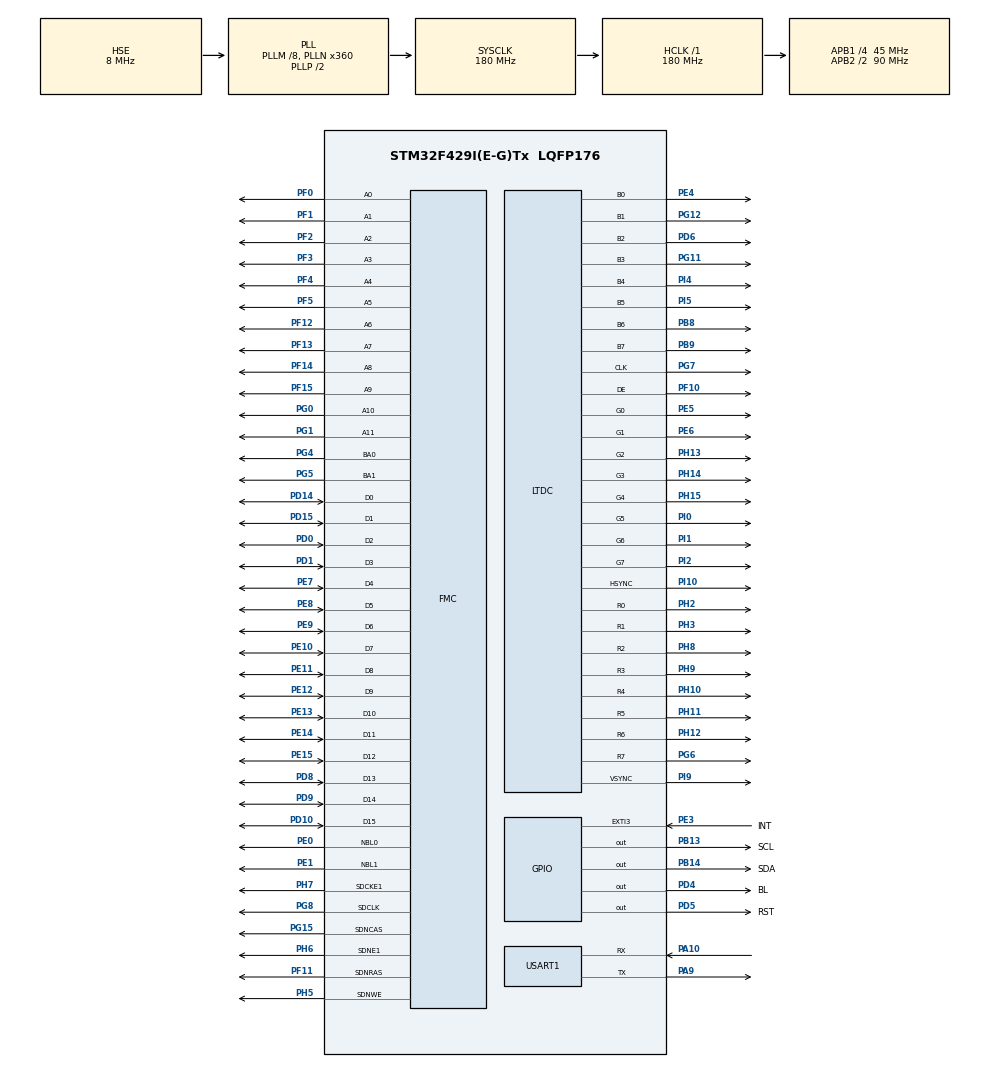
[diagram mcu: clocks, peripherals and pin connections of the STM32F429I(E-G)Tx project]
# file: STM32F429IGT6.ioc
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DMA2D.ColorMode=DMA2D_OUTPUT_RGB565
FMC.CASLatency1=FMC_SDRAM_CAS_LATENCY_3
FMC.ExitSelfRefreshDelay1=7
FMC.LoadToActiveDelay1=2
FMC.RCDDelay1=2
FMC.RPDelay1=2
FMC.ReadPipeDelay1=FMC_SDRAM_RPIPE_DELAY_1
FMC.RowCycleDelay1=6
FMC.SDClockPeriod1=FMC_SDRAM_CLOCK_PERIOD_2
FMC.SelfRefreshTime1=4
FMC.WriteRecoveryTime1=2
LTDC.ActiveW=800
LTDC.Alpha_L0=255
LTDC.FBStartAdress_L0=0xD0000000
LTDC.FBStartAdress_L1=0xD0200000
LTDC.HBP=30
LTDC.HFP=210
LTDC.HSync=30
LTDC.ImageHeight_L0=480
LTDC.ImageHeight_L1=480
LTDC.ImageWidth_L0=800
LTDC.ImageWidth_L1=800
LTDC.PixelFormat_L0=LTDC_PIXEL_FORMAT_RGB565
LTDC.PixelFormat_L1=LTDC_PIXEL_FORMAT_RGB565
LTDC.VBP=4
LTDC.VFP=4
LTDC.WindowX1_L0=800
LTDC.WindowX1_L1=800
LTDC.WindowY1_L0=480
LTDC.WindowY1_L1=480
Mcu.Family=STM32F4
Mcu.Name=STM32F429I(E-G)Tx
Mcu.Package=LQFP176
NVIC.EXTI3_IRQn=true\:3\:0\:true\:false\:true\:true
NVIC.PriorityGroup=NVIC_PRIORITYGROUP_4
PA10.Mode=Asynchronous
PA10.Signal=USART1_RX
PA9.Mode=Asynchronous
PA9.Signal=USART1_TX
PB13.GPIO_Label=SCL
PB13.GPIO_PuPd=GPIO_PULLUP
PB13.Signal=GPIO_Output
PB14.GPIO_Label=SDA
PB14.GPIO_PuPd=GPIO_PULLUP
PB14.Signal=GPIO_Output
PB8.GPIO_Speed=GPIO_SPEED_FREQ_VERY_HIGH
PB8.Mode=RGB888
PB8.Signal=LTDC_B6
PB9.GPIO_Speed=GPIO_SPEED_FREQ_VERY_HIGH
PB9.Mode=RGB888
PB9.Signal=LTDC_B7
PD0.Signal=FMC_D2_DA2
PD1.Signal=FMC_D3_DA3
PD10.Signal=FMC_D15_DA15
PD14.Signal=FMC_D0_DA0
PD15.Signal=FMC_D1_DA1
PD4.GPIO_Label=BL
PD4.GPIO_PuPd=GPIO_NOPULL
PD4.PinState=GPIO_PIN_RESET
PD4.Signal=GPIO_Output
PD5.GPIO_Label=RST
PD5.GPIO_PuPd=GPIO_PULLUP
PD5.Signal=GPIO_Output
PD6.GPIO_Speed=GPIO_SPEED_FREQ_VERY_HIGH
PD6.Mode=RGB888
PD6.Signal=LTDC_B2
PD8.Signal=FMC_D13_DA13
PD9.Signal=FMC_D14_DA14
PE0.Signal=FMC_NBL0
PE1.Signal=FMC_NBL1
PE10.Signal=FMC_D7_DA7
PE11.Signal=FMC_D8_DA8
PE12.Signal=FMC_D9_DA9
PE13.Signal=FMC_D10_DA10
PE14.Signal=FMC_D11_DA11
PE15.Signal=FMC_D12_DA12
PE3.GPIO_Label=INT
PE3.GPIO_ModeDefaultEXTI=GPIO_MODE_IT_FALLING
PE3.GPIO_PuPd=GPIO_PULLUP
PE3.Signal=GPXTI3
PE4.GPIO_Speed=GPIO_SPEED_FREQ_VERY_HIGH
PE4.Mode=RGB888
PE4.Signal=LTDC_B0
PE5.GPIO_Speed=GPIO_SPEED_FREQ_VERY_HIGH
PE5.Mode=RGB888
PE5.Signal=LTDC_G0
PE6.GPIO_Speed=GPIO_SPEED_FREQ_VERY_HIGH
PE6.Mode=RGB888
PE6.Signal=LTDC_G1
PE7.Signal=FMC_D4_DA4
PE8.Signal=FMC_D5_DA5
PE9.Signal=FMC_D6_DA6
PF0.Signal=FMC_A0
PF1.Signal=FMC_A1
PF10.GPIO_Speed=GPIO_SPEED_FREQ_VERY_HIGH
PF10.Mode=RGB888
PF10.Signal=LTDC_DE
PF11.Signal=FMC_SDNRAS
PF12.Signal=FMC_A6
PF13.Signal=FMC_A7
PF14.Signal=FMC_A8
PF15.Signal=FMC_A9
PF2.Signal=FMC_A2
PF3.Signal=FMC_A3
PF4.Signal=FMC_A4
PF5.Signal=FMC_A5
PG0.Signal=FMC_A10
PG1.Signal=FMC_A11
PG11.GPIO_Speed=GPIO_SPEED_FREQ_VERY_HIGH
PG11.Mode=RGB888
PG11.Signal=LTDC_B3
PG12.GPIO_Speed=GPIO_SPEED_FREQ_VERY_HIGH
PG12.Mode=RGB888
PG12.Signal=LTDC_B1
PG15.Signal=FMC_SDNCAS
PG4.Signal=FMC_A14_BA0
PG5.Signal=FMC_A15_BA1
PG6.GPIO_Speed=GPIO_SPEED_FREQ_VERY_HIGH
PG6.Mode=RGB888
PG6.Signal=LTDC_R7
PG7.GPIO_Speed=GPIO_SPEED_FREQ_VERY_HIGH
PG7.Mode=RGB888
PG7.Signal=LTDC_CLK
PG8.Signal=FMC_SDCLK
PH0/OSC_IN.Mode=HSE-External-Oscillator
PH0/OSC_IN.Signal=RCC_OSC_IN
PH1/OSC_OUT.Mode=HSE-External-Oscillator
PH1/OSC_OUT.Signal=RCC_OSC_OUT
PH10.GPIO_Speed=GPIO_SPEED_FREQ_VERY_HIGH
PH10.Mode=RGB888
PH10.Signal=LTDC_R4
PH11.GPIO_Speed=GPIO_SPEED_FREQ_VERY_HIGH
PH11.Mode=RGB888
PH11.Signal=LTDC_R5
PH12.GPIO_Speed=GPIO_SPEED_FREQ_VERY_HIGH
PH12.Mode=RGB888
PH12.Signal=LTDC_R6
PH13.GPIO_Speed=GPIO_SPEED_FREQ_VERY_HIGH
PH13.Mode=RGB888
PH13.Signal=LTDC_G2
PH14.GPIO_Speed=GPIO_SPEED_FREQ_VERY_HIGH
PH14.Mode=RGB888
PH14.Signal=LTDC_G3
PH15.GPIO_Speed=GPIO_SPEED_FREQ_VERY_HIGH
PH15.Mode=RGB888
PH15.Signal=LTDC_G4
PH2.GPIO_Speed=GPIO_SPEED_FREQ_VERY_HIGH
PH2.Mode=RGB888
PH2.Signal=LTDC_R0
PH3.GPIO_Speed=GPIO_SPEED_FREQ_VERY_HIGH
PH3.Mode=RGB888
PH3.Signal=LTDC_R1
PH5.Signal=FMC_SDNWE
PH6.Mode=SdramChipSelect2_1
PH6.Signal=FMC_SDNE1
PH7.Mode=SdramChipSelect2_1
PH7.Signal=FMC_SDCKE1
PH8.GPIO_Speed=GPIO_SPEED_FREQ_VERY_HIGH
PH8.Mode=RGB888
PH8.Signal=LTDC_R2
PH9.GPIO_Speed=GPIO_SPEED_FREQ_VERY_HIGH
PH9.Mode=RGB888
PH9.Signal=LTDC_R3
PI0.GPIO_Speed=GPIO_SPEED_FREQ_VERY_HIGH
PI0.Mode=RGB888
PI0.Signal=LTDC_G5
PI1.GPIO_Speed=GPIO_SPEED_FREQ_VERY_HIGH
PI1.Mode=RGB888
PI1.Signal=LTDC_G6
PI10.GPIO_Speed=GPIO_SPEED_FREQ_VERY_HIGH
PI10.Mode=RGB888
PI10.Signal=LTDC_HSYNC
PI2.GPIO_Speed=GPIO_SPEED_FREQ_VERY_HIGH
PI2.Mode=RGB888
PI2.Signal=LTDC_G7
PI4.GPIO_Speed=GPIO_SPEED_FREQ_VERY_HIGH
PI4.Mode=RGB888
PI4.Signal=LTDC_B4
PI5.GPIO_Speed=GPIO_SPEED_FREQ_VERY_HIGH
PI5.Mode=RGB888
PI5.Signal=LTDC_B5
PI9.GPIO_Speed=GPIO_SPEED_FREQ_VERY_HIGH
PI9.Mode=RGB888
PI9.Signal=LTDC_VSYNC
ProjectManager.HeapSize=0x200
ProjectManager.StackSize=0x400
ProjectManager.TargetToolchain=MDK-ARM V5
RCC.48MHZClocksFreq_Value=90000000
RCC.AHBFreq_Value=180000000
RCC.APB1CLKDivider=RCC_HCLK_DIV4
RCC.APB1Freq_Value=45000000
RCC.APB1TimFreq_Value=90000000
RCC.APB2CLKDivider=RCC_HCLK_DIV2
RCC.APB2Freq_Value=90000000
RCC.APB2TimFreq_Value=180000000
RCC.CortexFreq_Value=180000000
RCC.HCLKFreq_Value=180000000
RCC.HSE_VALUE=8000000
RCC.HSI_VALUE=16000000
RCC.LSE_VALUE=32768
RCC.PLLM=8
RCC.PLLN=360
RCC.PLLSAIN=152
RCC.PLLSourceVirtual=RCC_PLLSOURCE_HSE
RCC.SYSCLKFreq_VALUE=180000000
RCC.SYSCLKSource=RCC_SYSCLKSOURCE_PLLCLK
RCC.VCOOutputFreq_Value=360000000
SH.FMC_A0.0=FMC_A0,12b-sda1
SH.FMC_A1.0=FMC_A1,12b-sda1
SH.FMC_A10.0=FMC_A10,12b-sda1
SH.FMC_A11.0=FMC_A11,12b-sda1
SH.FMC_A14_BA0.0=FMC_BA0,FourSdramBanks1
SH.FMC_A15_BA1.0=FMC_BA1,FourSdramBanks1
SH.FMC_A2.0=FMC_A2,12b-sda1
SH.FMC_A3.0=FMC_A3,12b-sda1
SH.FMC_A4.0=FMC_A4,12b-sda1
SH.FMC_A5.0=FMC_A5,12b-sda1
SH.FMC_A6.0=FMC_A6,12b-sda1
SH.FMC_A7.0=FMC_A7,12b-sda1
SH.FMC_A8.0=FMC_A8,12b-sda1
SH.FMC_A9.0=FMC_A9,12b-sda1
SH.FMC_D0_DA0.0=FMC_D0,sd-16b-d1
SH.FMC_D10_DA10.0=FMC_D10,sd-16b-d1
SH.FMC_D11_DA11.0=FMC_D11,sd-16b-d1
SH.FMC_D12_DA12.0=FMC_D12,sd-16b-d1
SH.FMC_D13_DA13.0=FMC_D13,sd-16b-d1
SH.FMC_D14_DA14.0=FMC_D14,sd-16b-d1
SH.FMC_D15_DA15.0=FMC_D15,sd-16b-d1
SH.FMC_D1_DA1.0=FMC_D1,sd-16b-d1
SH.FMC_D2_DA2.0=FMC_D2,sd-16b-d1
SH.FMC_D3_DA3.0=FMC_D3,sd-16b-d1
SH.FMC_D4_DA4.0=FMC_D4,sd-16b-d1
SH.FMC_D5_DA5.0=FMC_D5,sd-16b-d1
SH.FMC_D6_DA6.0=FMC_D6,sd-16b-d1
SH.FMC_D7_DA7.0=FMC_D7,sd-16b-d1
SH.FMC_D8_DA8.0=FMC_D8,sd-16b-d1
SH.FMC_D9_DA9.0=FMC_D9,sd-16b-d1
SH.FMC_NBL0.0=FMC_NBL0,Sd2ByteEnable1
SH.FMC_NBL1.0=FMC_NBL1,Sd2ByteEnable1
SH.FMC_SDCLK.0=FMC_SDCLK,12b-sda1
SH.FMC_SDNCAS.0=FMC_SDNCAS,12b-sda1
SH.FMC_SDNRAS.0=FMC_SDNRAS,12b-sda1
SH.FMC_SDNWE.0=FMC_SDNWE,12b-sda1
USART1.VirtualMode=VM_ASYNC
VP_DMA2D_VS_DMA2D.Mode=DMA2D_Activate
board=custom

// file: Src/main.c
/* USER CODE BEGIN Header */
/**
  ******************************************************************************
  * @file           : main.c
  * @brief          : Main program body
  ******************************************************************************
  ** This notice applies to any and all portions of this file
  * that are not between comment pairs USER CODE BEGIN and
  * USER CODE END. Other portions of this file, whether
  * inserted by the user or by software development tools
  * are owned by their respective copyright owners.
  *
  * COPYRIGHT(c) 2019 STMicroelectronics
  *
  * Redistribution and use in source and binary forms, with or without modification,
  * are permitted provided that the following conditions are met:
  *   1. Redistributions of source code must retain the above copyright notice,
  *      this list of conditions and the following disclaimer.
  *   2. Redistributions in binary form must reproduce the above copyright notice,
  *      this list of conditions and the following disclaimer in the documentation
  *      and/or other materials provided with the distribution.
  *   3. Neither the name of STMicroelectronics nor the names of its contributors
  *      may be used to endorse or promote products derived from this software
  *      without specific prior written permission.
  *
  * THIS SOFTWARE IS PROVIDED BY THE COPYRIGHT HOLDERS AND CONTRIBUTORS "AS IS"
  * AND ANY EXPRESS OR IMPLIED WARRANTIES, INCLUDING, BUT NOT LIMITED TO, THE
  * IMPLIED WARRANTIES OF MERCHANTABILITY AND FITNESS FOR A PARTICULAR PURPOSE ARE
  * DISCLAIMED. IN NO EVENT SHALL THE COPYRIGHT HOLDER OR CONTRIBUTORS BE LIABLE
  * FOR ANY DIRECT, INDIRECT, INCIDENTAL, SPECIAL, EXEMPLARY, OR CONSEQUENTIAL
  * DAMAGES (INCLUDING, BUT NOT LIMITED TO, PROCUREMENT OF SUBSTITUTE GOODS OR
  * SERVICES; LOSS OF USE, DATA, OR PROFITS; OR BUSINESS INTERRUPTION) HOWEVER
  * CAUSED AND ON ANY THEORY OF LIABILITY, WHETHER IN CONTRACT, STRICT LIABILITY,
  * OR TORT (INCLUDING NEGLIGENCE OR OTHERWISE) ARISING IN ANY WAY OUT OF THE USE
  * OF THIS SOFTWARE, EVEN IF ADVISED OF THE POSSIBILITY OF SUCH DAMAGE.
  *
  ******************************************************************************
  */
/* USER CODE END Header */

#include "main.h"
#include "dma2d.h"
#include "ltdc.h"
#include "usart.h"
#include "gpio.h"
#include "fmc.h"

/* USER CODE BEGIN Includes */
#include "BSP_RGB_LCD.h"
#include "GT911.h"
#include "image.h"
/* USER CODE END Includes */

/* USER CODE BEGIN PTD */
extern GT911_Dev Dev_Now;

void HAL_GPIO_EXTI_Callback(uint16_t GPIO_Pin)
{
	if(GPIO_Pin == GPIO_PIN_3)
	{
		Dev_Now.Touch = 1;
		GT911_Scan();
	}
}
/* USER CODE END PTD */

void SystemClock_Config(void);

int main(void)
{

  /* MCU Configuration--------------------------------------------------------*/

  /* Reset of all peripherals, Initializes the Flash interface and the Systick. */
  HAL_Init();

  /* Configure the system clock */
  SystemClock_Config();

  /* Initialize all configured peripherals */
  MX_GPIO_Init();
  MX_FMC_Init();
  MX_USART1_UART_Init();
  MX_LTDC_Init();
  MX_DMA2D_Init();
  /* USER CODE BEGIN 2 */
	printf("\r\n SDRAM example !!!\r\n");
	/* Initialize the LCD */
	BSP_LCD_Init();

	Paint_NewImage(LCD_WIDTH, LCD_HEIGHT, 0, WHITE);
	Paint_Clear(WHITE);

	Paint_DrawString_EN(10, 230, "1234567890", &Font24, 0x000f, 0xfff0);
	Paint_DrawString_EN(10, 260, "ABCDEFGHIJ", &Font24, BLUE, CYAN);
	Paint_DrawString_CN(10, 290, "微雪电子", &Font24CN, BLUE, CYAN);

	Paint_DrawRectangle(200, 230, 300, 330, RED,DRAW_FILL_EMPTY, DOT_PIXEL_2X2 );
	Paint_DrawLine(200, 230, 300, 330, MAGENTA, LINE_STYLE_SOLID, DOT_PIXEL_2X2);
	Paint_DrawLine(300, 230, 200, 330, MAGENTA, LINE_STYLE_SOLID, DOT_PIXEL_2X2);
	Paint_DrawCircle(250, 280, 45, GREEN, DRAW_FILL_EMPTY, DOT_PIXEL_2X2);
	Paint_DrawImage(gImage_800X221, 0, 0, 800, 221);
	GT911_Init();
  /* USER CODE END 2 */

  /* Infinite loop */
  while (1)
  {

  }
}

void SystemClock_Config(void)
{
  RCC_OscInitTypeDef RCC_OscInitStruct = {0};
  RCC_ClkInitTypeDef RCC_ClkInitStruct = {0};
  RCC_PeriphCLKInitTypeDef PeriphClkInitStruct = {0};

  /**Configure the main internal regulator output voltage
  */
  __HAL_RCC_PWR_CLK_ENABLE();
  __HAL_PWR_VOLTAGESCALING_CONFIG(PWR_REGULATOR_VOLTAGE_SCALE1);
  /**Initializes the CPU, AHB and APB busses clocks
  */
  RCC_OscInitStruct.OscillatorType = RCC_OSCILLATORTYPE_HSE;
  RCC_OscInitStruct.HSEState = RCC_HSE_ON;
  RCC_OscInitStruct.PLL.PLLState = RCC_PLL_ON;
  RCC_OscInitStruct.PLL.PLLSource = RCC_PLLSOURCE_HSE;
  RCC_OscInitStruct.PLL.PLLM = 8;
  RCC_OscInitStruct.PLL.PLLN = 360;
  RCC_OscInitStruct.PLL.PLLP = RCC_PLLP_DIV2;
  RCC_OscInitStruct.PLL.PLLQ = 4;
  if (HAL_RCC_OscConfig(&RCC_OscInitStruct) != HAL_OK)
  {
    Error_Handler();
  }
  /**Activate the Over-Drive mode
  */
  if (HAL_PWREx_EnableOverDrive() != HAL_OK)
  {
    Error_Handler();
  }
  /**Initializes the CPU, AHB and APB busses clocks
  */
  RCC_ClkInitStruct.ClockType = RCC_CLOCKTYPE_HCLK|RCC_CLOCKTYPE_SYSCLK
                              |RCC_CLOCKTYPE_PCLK1|RCC_CLOCKTYPE_PCLK2;
  RCC_ClkInitStruct.SYSCLKSource = RCC_SYSCLKSOURCE_PLLCLK;
  RCC_ClkInitStruct.AHBCLKDivider = RCC_SYSCLK_DIV1;
  RCC_ClkInitStruct.APB1CLKDivider = RCC_HCLK_DIV4;
  RCC_ClkInitStruct.APB2CLKDivider = RCC_HCLK_DIV2;

  if (HAL_RCC_ClockConfig(&RCC_ClkInitStruct, FLASH_LATENCY_5) != HAL_OK)
  {
    Error_Handler();
  }
  PeriphClkInitStruct.PeriphClockSelection = RCC_PERIPHCLK_LTDC;
  PeriphClkInitStruct.PLLSAI.PLLSAIN = 152;
  PeriphClkInitStruct.PLLSAI.PLLSAIR = 2;
  PeriphClkInitStruct.PLLSAIDivR = RCC_PLLSAIDIVR_2;
  if (HAL_RCCEx_PeriphCLKConfig(&PeriphClkInitStruct) != HAL_OK)
  {
    Error_Handler();
  }
}

void Error_Handler(void)
{
}

/************************ (C) COPYRIGHT STMicroelectronics *****END OF FILE****/
